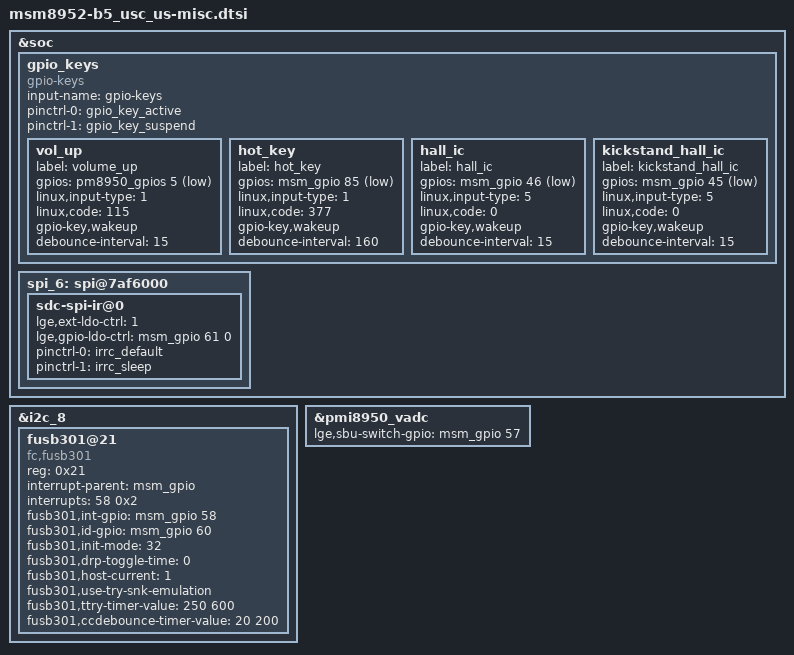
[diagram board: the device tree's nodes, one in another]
/*
 * Copyright (c) 2015, The Linux Foundation. All rights reserved.
 *
 * This program is free software; you can redistribute it and/or modify
 * it under the terms of the GNU General Public License version 2 and
 * only version 2 as published by the Free Software Foundation.
 *
 * This program is distributed in the hope that it will be useful,
 * but WITHOUT ANY WARRANTY; without even the implied warranty of
 * MERCHANTABILITY or FITNESS FOR A PARTICULAR PURPOSE.  See the
 * GNU General Public License for more details.
 */

&soc {
	gpio_keys {
		compatible = "gpio-keys";
		input-name = "gpio-keys";
		pinctrl-names = "tlmm_gpio_key_active","tlmm_gpio_key_suspend";
		pinctrl-0 = <&gpio_key_active>;
		pinctrl-1 = <&gpio_key_suspend>;

		vol_up {
			label = "volume_up";
			gpios = <&pm8950_gpios 5 0x1>;
			linux,input-type = <1>;
			linux,code = <115>;
			gpio-key,wakeup;
			debounce-interval = <15>;
		};

		hot_key {
			label = "hot_key";
			gpios = <&msm_gpio 85 0x1>;
			linux,input-type = <1>;
			linux,code = <377>;
			gpio-key,wakeup;
			debounce-interval = <160>;
		};

		hall_ic {
			label = "hall_ic";
			gpios = <&msm_gpio 46 0x1>;
			linux,input-type = <5>;
			linux,code = <0>;
			gpio-key,wakeup;
			debounce-interval = <15>;
		};

		kickstand_hall_ic {
			label = "kickstand_hall_ic";
			gpios = <&msm_gpio 45 0x1>;
			linux,input-type = <5>;
			linux,code = <0>;
			gpio-key,wakeup;
			debounce-interval = <15>;
		};

	};
	spi_6: spi@7af6000 {
		sdc-spi-ir@0 {
			lge,ext-ldo-ctrl = <1>;
			lge,gpio-ldo-ctrl = <&msm_gpio 61 0>;
			pinctrl-names = "irrc_default", "irrc_sleep";
			pinctrl-0 = <&irrc_default>;
			pinctrl-1 = <&irrc_sleep>;
		};
	};
};

&i2c_8 {
	fusb301@21 {
		status = "ok";
		compatible = "fc,fusb301";
		reg = <0x21>;
		interrupt-parent = <&msm_gpio>;
		interrupts = <58 0x2>;
		fusb301,int-gpio = <&msm_gpio 58 0>; /* CC_CTRL_INT_N */
		fusb301,id-gpio = <&msm_gpio 60 0>;   /* DETECT_CC Interrupt Pin */
		fusb301,init-mode = /bits/ 8 <32>;
		fusb301,drp-toggle-time = /bits/ 8 <0>;
		fusb301,host-current = /bits/ 8 <1>;
		fusb301,use-try-snk-emulation;
		fusb301,ttry-timer-value = <250 600>;
		fusb301,ccdebounce-timer-value = <20 200>;

	};
};


&pmi8950_vadc {
        lge,sbu-switch-gpio = <&msm_gpio 57 0>; /* Switch for SBU (USB_SW_EN) */
};

